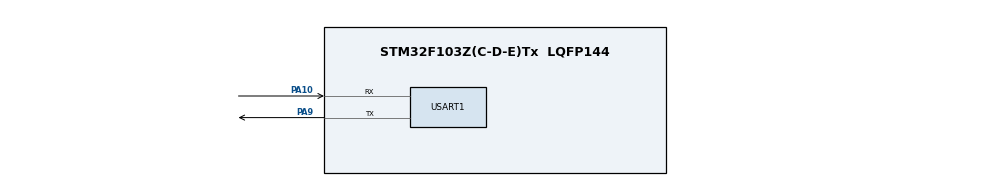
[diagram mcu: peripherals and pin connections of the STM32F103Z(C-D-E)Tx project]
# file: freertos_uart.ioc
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Dma.Request0=USART1_RX
Dma.Request1=USART1_TX
Dma.USART1_RX.0.Direction=DMA_PERIPH_TO_MEMORY
Dma.USART1_RX.0.Instance=DMA1_Channel5
Dma.USART1_RX.0.MemDataAlignment=DMA_MDATAALIGN_BYTE
Dma.USART1_RX.0.MemInc=DMA_MINC_ENABLE
Dma.USART1_RX.0.Mode=DMA_NORMAL
Dma.USART1_RX.0.PeriphDataAlignment=DMA_PDATAALIGN_BYTE
Dma.USART1_RX.0.PeriphInc=DMA_PINC_DISABLE
Dma.USART1_RX.0.Priority=DMA_PRIORITY_LOW
Dma.USART1_TX.1.Direction=DMA_MEMORY_TO_PERIPH
Dma.USART1_TX.1.Instance=DMA1_Channel4
Dma.USART1_TX.1.MemDataAlignment=DMA_MDATAALIGN_BYTE
Dma.USART1_TX.1.MemInc=DMA_MINC_ENABLE
Dma.USART1_TX.1.Mode=DMA_NORMAL
Dma.USART1_TX.1.PeriphDataAlignment=DMA_PDATAALIGN_BYTE
Dma.USART1_TX.1.PeriphInc=DMA_PINC_DISABLE
Dma.USART1_TX.1.Priority=DMA_PRIORITY_LOW
FREERTOS.Tasks01=defaultTask,24,128,StartDefaultTask,Default,NULL,Dynamic,NULL,NULL
Mcu.Family=STM32F1
Mcu.Name=STM32F103Z(C-D-E)Tx
Mcu.Package=LQFP144
NVIC.DMA1_Channel4_IRQn=true\:5\:0\:false\:false\:true\:true\:false\:true\:true
NVIC.DMA1_Channel5_IRQn=true\:5\:0\:false\:false\:true\:true\:false\:true\:true
NVIC.PriorityGroup=NVIC_PRIORITYGROUP_4
NVIC.TIM1_UP_IRQn=true\:15\:0\:false\:false\:true\:false\:false\:true\:true
NVIC.TimeBase=TIM1_UP_IRQn
NVIC.TimeBaseIP=TIM1
NVIC.USART1_IRQn=true\:5\:0\:false\:false\:true\:true\:true\:true\:true
PA10.Mode=Asynchronous
PA10.Signal=USART1_RX
PA13.Mode=Serial_Wire
PA13.Signal=SYS_JTMS-SWDIO
PA14.Mode=Serial_Wire
PA14.Signal=SYS_JTCK-SWCLK
PA9.Mode=Asynchronous
PA9.Signal=USART1_TX
ProjectManager.HeapSize=0x200
ProjectManager.StackSize=0x400
ProjectManager.TargetToolchain=MDK-ARM V5.32
RCC.APB1Freq_Value=8000000
RCC.APB2Freq_Value=8000000
USART1.VirtualMode=VM_ASYNC
VP_FREERTOS_VS_CMSIS_V2.Mode=CMSIS_V2
VP_SYS_VS_tim1.Mode=TIM1
board=custom

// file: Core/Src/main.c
/* USER CODE BEGIN Header */
/**
  ******************************************************************************
  * @file           : main.c
  * @brief          : Main program body
  ******************************************************************************
  * @attention
  *
  * Copyright (c) 2024 STMicroelectronics.
  * All rights reserved.
  *
  * This software is licensed under terms that can be found in the LICENSE file
  * in the root directory of this software component.
  * If no LICENSE file comes with this software, it is provided AS-IS.
  *
  ******************************************************************************
  */
/* USER CODE END Header */
#include "main.h"
#include "cmsis_os.h"

/* USER CODE BEGIN Includes */
#include "uart_device.h"

/* USER CODE END Includes */

UART_HandleTypeDef huart1;
DMA_HandleTypeDef hdma_usart1_rx;
DMA_HandleTypeDef hdma_usart1_tx;

/* Definitions for defaultTask */
osThreadId_t defaultTaskHandle;
const osThreadAttr_t defaultTask_attributes = {
  .name = "defaultTask",
  .stack_size = 128 * 4,
  .priority = (osPriority_t) osPriorityNormal,
};

void SystemClock_Config(void);
static void MX_GPIO_Init(void);
static void MX_DMA_Init(void);
static void MX_USART1_UART_Init(void);
void StartDefaultTask(void *argument);

int main(void)
{
  /* USER CODE BEGIN 1 */
  char c;

  /* USER CODE END 1 */

  /* MCU Configuration--------------------------------------------------------*/

  /* Reset of all peripherals, Initializes the Flash interface and the Systick. */
  HAL_Init();

  /* Configure the system clock */
  SystemClock_Config();

  /* Initialize all configured peripherals */
  MX_GPIO_Init();
  MX_DMA_Init();
  MX_USART1_UART_Init();

  /* Init scheduler */
  osKernelInitialize();

  /* Create the thread(s) */
  /* creation of defaultTask */
  defaultTaskHandle = osThreadNew(StartDefaultTask, NULL, &defaultTask_attributes);

  /* Start scheduler */
  osKernelStart();

  /* We should never get here as control is now taken by the scheduler */
  /* Infinite loop */
  while (1)
  {

  }
}

void SystemClock_Config(void)
{
  RCC_OscInitTypeDef RCC_OscInitStruct = {0};
  RCC_ClkInitTypeDef RCC_ClkInitStruct = {0};

  /** Initializes the RCC Oscillators according to the specified parameters
  * in the RCC_OscInitTypeDef structure.
  */
  RCC_OscInitStruct.OscillatorType = RCC_OSCILLATORTYPE_HSI;
  RCC_OscInitStruct.HSIState = RCC_HSI_ON;
  RCC_OscInitStruct.HSICalibrationValue = RCC_HSICALIBRATION_DEFAULT;
  RCC_OscInitStruct.PLL.PLLState = RCC_PLL_NONE;
  if (HAL_RCC_OscConfig(&RCC_OscInitStruct) != HAL_OK)
  {
    Error_Handler();
  }

  /** Initializes the CPU, AHB and APB buses clocks
  */
  RCC_ClkInitStruct.ClockType = RCC_CLOCKTYPE_HCLK|RCC_CLOCKTYPE_SYSCLK
                              |RCC_CLOCKTYPE_PCLK1|RCC_CLOCKTYPE_PCLK2;
  RCC_ClkInitStruct.SYSCLKSource = RCC_SYSCLKSOURCE_HSI;
  RCC_ClkInitStruct.AHBCLKDivider = RCC_SYSCLK_DIV1;
  RCC_ClkInitStruct.APB1CLKDivider = RCC_HCLK_DIV1;
  RCC_ClkInitStruct.APB2CLKDivider = RCC_HCLK_DIV1;

  if (HAL_RCC_ClockConfig(&RCC_ClkInitStruct, FLASH_LATENCY_0) != HAL_OK)
  {
    Error_Handler();
  }
}

static void MX_USART1_UART_Init(void)
{

  huart1.Instance = USART1;
  huart1.Init.BaudRate = 115200;
  huart1.Init.WordLength = UART_WORDLENGTH_8B;
  huart1.Init.StopBits = UART_STOPBITS_1;
  huart1.Init.Parity = UART_PARITY_NONE;
  huart1.Init.Mode = UART_MODE_TX_RX;
  huart1.Init.HwFlowCtl = UART_HWCONTROL_NONE;
  huart1.Init.OverSampling = UART_OVERSAMPLING_16;
  if (HAL_UART_Init(&huart1) != HAL_OK)
  {
    Error_Handler();
  }

}

static void MX_DMA_Init(void)
{

  /* DMA controller clock enable */
  __HAL_RCC_DMA1_CLK_ENABLE();

  /* DMA interrupt init */
  /* DMA1_Channel4_IRQn interrupt configuration */
  HAL_NVIC_SetPriority(DMA1_Channel4_IRQn, 5, 0);
  HAL_NVIC_EnableIRQ(DMA1_Channel4_IRQn);
  /* DMA1_Channel5_IRQn interrupt configuration */
  HAL_NVIC_SetPriority(DMA1_Channel5_IRQn, 5, 0);
  HAL_NVIC_EnableIRQ(DMA1_Channel5_IRQn);

}

static void MX_GPIO_Init(void)
{

  /* GPIO Ports Clock Enable */
  __HAL_RCC_GPIOA_CLK_ENABLE();

}

void StartDefaultTask(void *argument)
{
  /* USER CODE BEGIN 5 */
    char c;
    //struct UART_Device *pUARTDev = GetUARTDevice("stm32_uart1");
    //struct UART_Device *pUARTDev = GetUARTDevice("stm32_bear_uart1");
    struct UART_Device *pUARTDev = GetUARTDevice("stm32_dma_uart1");

    pUARTDev->Init(pUARTDev, 115200, 8, 'N', 1);

  /* Infinite loop */
  for(;;)
  {
      //HAL_UART_Transmit_IT(&huart1, "100ask\r\n", 8);
      //HAL_Delay(100);
      pUARTDev->Send(pUARTDev, "100ask\r\n", 8, 100);

      //while (HAL_OK != HAL_UART_Receive(&huart1, &c, 1, 100));
      while (0 != pUARTDev->Recv(pUARTDev, &c, 100));
      c++;
      //HAL_UART_Transmit_IT(&huart1, &c, 1);
      //HAL_Delay(1);

      pUARTDev->Send(pUARTDev, &c, 1, 1);
  }
  /* USER CODE END 5 */
}

void HAL_TIM_PeriodElapsedCallback(TIM_HandleTypeDef *htim)
{
  if (htim->Instance == TIM1) {
    HAL_IncTick();
  }
}

void Error_Handler(void)
{
  __disable_irq();
  while (1)
  {
  }
}
